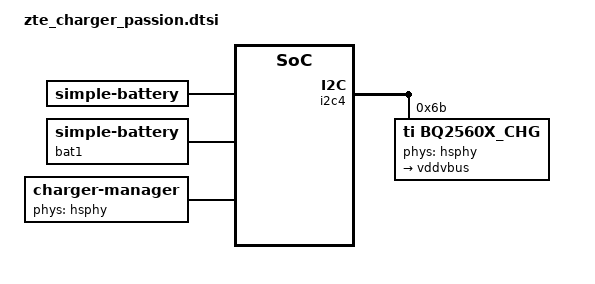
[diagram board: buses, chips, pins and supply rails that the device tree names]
/ {
	bat: battery {
		compatible = "simple-battery";
		charge-full-design-microamp-hours = <2780000>;
		charge-term-current-microamp = <120000>;
		constant_charge_voltage_max_microvolt = <4350000>;
		factory-internal-resistance-micro-ohms = <320000>;
		voltage-min-design-microvolt = <3450000>;
		ocv-capacity-celsius = <20>;
		ocv-capacity-table-0 = <4330000 100>, <4249000 95>, <4189000 90>,
					<4133000 85>, <4081000 80>, <4034000 75>,
					<3991000 70>, <3953000 65>, <3910000 60>,
					<3866000 55>, <3836000 50>, <3813000 45>,
					<3795000 40>, <3782000 35>, <3774000 30>,
					<3765000 25>, <3750000 20>, <3726000 15>,
					<3687000 10>, <3658000 5>, <3400000 0>;
		voltage-temp-table = <1095000 800>, <986000 850>, <878000 900>,
					  <775000 950>, <678000 1000>, <590000 1050>,
					  <510000 1100>, <440000 1150>, <378000 1200>,
					  <324000 1250>, <278000 1300>, <238000 1350>,
					  <204000 1400>, <175000 1450>, <150000 1500>,
					  <129000 1550>, <111000 1600>, <96000 1650>;
		capacity-temp-table = <25 100>, <10 97>, <(-10) 60>;
		resistance-temp-table = <20 100>, <10 243>, <(-10) 468>;
		charge-sdp-current-microamp = <500000 500000>;
		charge-dcp-current-microamp = <1150000 3000000>;
		charge-cdp-current-microamp = <1150000 1150000>;
		charge-unknown-current-microamp = <500000 500000>;
	};

	bat1: battery1 {
		compatible = "simple-battery";
		charge-full-design-microamp-hours = <2780000>;
		charge-term-current-microamp = <120000>;
		constant_charge_voltage_max_microvolt = <4350000>;
		factory-internal-resistance-micro-ohms = <320000>;
		voltage-min-design-microvolt = <3450000>;
		ocv-capacity-celsius = <20>;
		ocv-capacity-table-0 = <4330000 100>, <4249000 95>, <4189000 90>,
					<4133000 85>, <4081000 80>, <4034000 75>,
					<3991000 70>, <3953000 65>, <3910000 60>,
					<3866000 55>, <3836000 50>, <3813000 45>,
					<3795000 40>, <3782000 35>, <3774000 30>,
					<3765000 25>, <3750000 20>, <3726000 15>,
					<3687000 10>, <3658000 5>, <3400000 0>;
		voltage-temp-table = <1095000 800>, <986000 850>, <878000 900>,
					  <775000 950>, <678000 1000>, <590000 1050>,
					  <510000 1100>, <440000 1150>, <378000 1200>,
					  <324000 1250>, <278000 1300>, <238000 1350>,
					  <204000 1400>, <175000 1450>, <150000 1500>,
					  <129000 1550>, <111000 1600>, <96000 1650>;
		capacity-temp-table = <25 100>, <10 97>, <(-10) 60>;
		resistance-temp-table = <20 100>, <10 243>, <(-10) 468>;
		charge-sdp-current-microamp = <500000 500000>;
		charge-dcp-current-microamp = <1150000 3000000>;
		charge-cdp-current-microamp = <1150000 1150000>;
		charge-unknown-current-microamp = <500000 500000>;
	};

	charger-manager {
		compatible = "charger-manager";
		cm-name = "battery";
		cm-poll-mode = <2>;
		cm-poll-interval = <15000>;
		cm-battery-stat = <2>;

		cm-fullbatt-vchkdrop-ms = <30000>;
		cm-fullbatt-vchkdrop-volt = <60000>;
		cm-fullbatt-voltage = <4330000>;
		cm-fullbatt-current = <120000>;
		cm-fullbatt-capacity = <100>;

		cm-num-chargers = <1>;
		cm-chargers = "fan54015_charger";
		cm-fuel-gauge = "sc27xx-fgu";

		/* in deci centigrade */
		cm-battery-cold = <200>;
		cm-battery-cold-in-minus;
		cm-battery-hot = <800>;
		cm-battery-temp-diff = <100>;

		/* Allow charging for 6hr */
		cm-charging-max = <21600000>;
		/* recovery charging after stop charging 45min */
		cm-discharging-max = <2700000>;

		/* the interval to feed charger watchdog */
		cm-wdt-interval = <60>;

		/* drop voltage in microVolts to allow shutdown */
		cm-shutdown-voltage = <3100000>;

		/* when 99% of the time is exceeded, it will be forced to 100% */
		cm-tickle-time-out = <1500>;

		/* how much time to allow capacity change */
		cm-one-cap-time = <30>;

		/* when the safe charging voltage is exceeded, stop charging */
		cm-charge-voltage-max = <6500000>;
		/* drop voltage in microVolts to restart charging */
		cm-charge-voltage-drop = <700000>;
		cm-dcp-jeita-temp-table = <1000 1030 0 4350000>, <1150 1180 700000 4350000>,
			<1450 1420 1150000 4350000>, <1600 1570 700000 4100000>;
		cm-sdp-jeita-temp-table = <1000 1030 0 4350000>, <1150 1180 500000 4350000>,
			<1450 1420 500000 4350000>, <1600 1570 500000 4100000>;
		cm-cdp-jeita-temp-table = <1000 1030 0 4350000>, <1150 1180 700000 4350000>,
			<1450 1420 1150000 4350000>, <1600 1570 700000 4100000>;
		cm-unknown-jeita-temp-table = <1000 1030 0 4350000>, <1150 1180 500000 4350000>,
			<1450 1420 500000 4350000>, <1600 1570 500000 4100000>;

		monitored-battery = <&bat>;
		cm-capacity-track;

		cm-cap-remap-table = <1 2 3>, <2 3 2>, <98 99 2>, <99 100 3>;

		regulator@0 {
			cm-regulator-name = "vddgen0";
			cable@0 {
				cm-cable-name = "USB";
				extcon = <&pmic_typec>;
			};
		};
	};
};

&bat {
	charge-full-design-microamp-hours = <3200000>;
	charge-term-current-microamp = <180000>;
	constant_charge_voltage_max_microvolt = <4400000>;
	constant_charge_current_max_microamp = <2170000>;
	factory-internal-resistance-micro-ohms = <254000>;
	voltage-min-design-microvolt = <3450000>;
	ocv-capacity-celsius = <25>;
	batt-id-list = <390 270>;  /* kohm, tianmao / weike */
	ocv-capacity-table-0 = <4362000 100>, <4303000 95>, <4246000 90>,
				<4191000 85>, <4137000 80>, <4085000 75>,
				<4038000 70>, <3992000 65>, <3945000 60>,
				<3890000 55>, <3857000 50>, <3832000 45>,
				<3812000 40>, <3795000 35>, <3779000 30>,
				<3759000 25>, <3739000 20>, <3714000 15>,
				<3686000 10>, <3672000 5>, <3400000 0>;
	/* NTC 47k, Vref 1850mV, R pull-up 56K, R pull-down 100k */
	voltage-temp-table = <1124352 750>, <1104007 800>, <1078598 850>,
				<1047499 900>, <1010247 950>, <966587 1000>,
				<916729 1050>, <861239 1100>, <801086 1150>,
				<737608 1200>, <672363 1250>, <607023 1300>,
				<543141 1350>, <482115 1400>, <424965 1450>,
				<372400 1500>, <324778 1550>, <282204 1600>,
				<244598 1650>, <208000 1700>, <178000 1750>;
	charge-sdp-current-microamp = <700000 500000>;
	charge-dcp-current-microamp = <2170000 1000000>;
	charge-cdp-current-microamp = <2170000 1000000>;
	charge-unknown-current-microamp = <700000 1000000>;
};

&bat1 {
	charge-full-design-microamp-hours = <3171000>;
	charge-term-current-microamp = <180000>;
	constant_charge_voltage_max_microvolt = <4400000>;
	constant_charge_current_max_microamp = <2170000>;
	factory-internal-resistance-micro-ohms = <139000>;
	voltage-min-design-microvolt = <3450000>;
	ocv-capacity-celsius = <25>;
	batt-id-list = <390 270>;  /* kohm, tianmao / weike */
	ocv-capacity-table-0 = <4370000 100>, <4304000 95>, <4245000 90>,
				<4187000 85>, <4132000 80>, <4080000 75>,
				<4031000 70>, <3982000 65>, <3944000 60>,
				<3892000 55>, <3852000 50>, <3827000 45>,
				<3807000 40>, <3791000 35>, <3778000 30>,
				<3761000 25>, <3743000 20>, <3719000 15>,
				<3689000 10>, <3678000 5>, <3400000 0>;
	/* NTC 47k, Vref 1850mV, R pull-up 56K, R pull-down 100k */
	voltage-temp-table = <1124352 750>, <1104007 800>, <1078598 850>,
				<1047499 900>, <1010247 950>, <966587 1000>,
				<916729 1050>, <861239 1100>, <801086 1150>,
				<737608 1200>, <672363 1250>, <607023 1300>,
				<543141 1350>, <482115 1400>, <424965 1450>,
				<372400 1500>, <324778 1550>, <282204 1600>,
				<244598 1650>, <208000 1700>, <178000 1750>;
	charge-sdp-current-microamp = <700000 500000>;
	charge-dcp-current-microamp = <2170000 1000000>;
	charge-cdp-current-microamp = <2170000 1000000>;
	charge-unknown-current-microamp = <700000 1000000>;
};

&pmic_fgu {
	monitored-battery = <&bat &bat1>;
	sprd,calib-resistance-real = <9900>;
	sprd,calib-resistance-spec = <20000>;
	io-channels = <&pmic_adc 0>, <&pmic_adc 3>, <&pmic_adc 14>;
	io-channel-names = "adc-batt-id", "bat-temp", "charge-vol";
};

/ {
	charger-manager {
		cm-fullbatt-voltage = <4350000>;
		cm-fullbatt-vchkdrop-volt = <50000>;
		cm-fullbatt-current = <180000>;
		cm-fullbatt-comp-voltage = <32000>;
		cm-thermal-limit = <2>;

		/* in deci centigrade */
		cm-battery-cold = <0>;
		cm-battery-hot = <550>;
		cm-battery-temp-diff = <30>;
		cm-tickle-time-out = <180>;

		cm-disable-charger-type-jeita;
		cm-jeita-temp-table = <1000 1030 0 4400000>,
				<1050 1080 310000 4400000>,
				<1100 1130 930000 4400000>,
				<1450 1420 2170000 4400000>,
				<1550 1520 1080000 4100000>;

		cm-chargers = "hook";
		cm-hardware-psy = "bq2560x_charger";
		/* cm-hardware-psy = "bq25601_charger"; */
		monitored-battery =<&bat &bat1>;
		phys = <&hsphy>;
	};
};

&i2c4 {
	status = "okay";
	bq2560x_chg: charger@6b {
		compatible = "ti,bq2560x_chg";
		reg = <0x6b>;
		phys = <&hsphy>;
		monitored-battery = <&bat>;
		extcon = <&extcon_gpio>;
		vddvbus:otg-vbus {
			regulator-name = "vddvbus";
		};
	};
};

#include "../bat_setting/battery_protect_policy_080509200080.dtsi"
